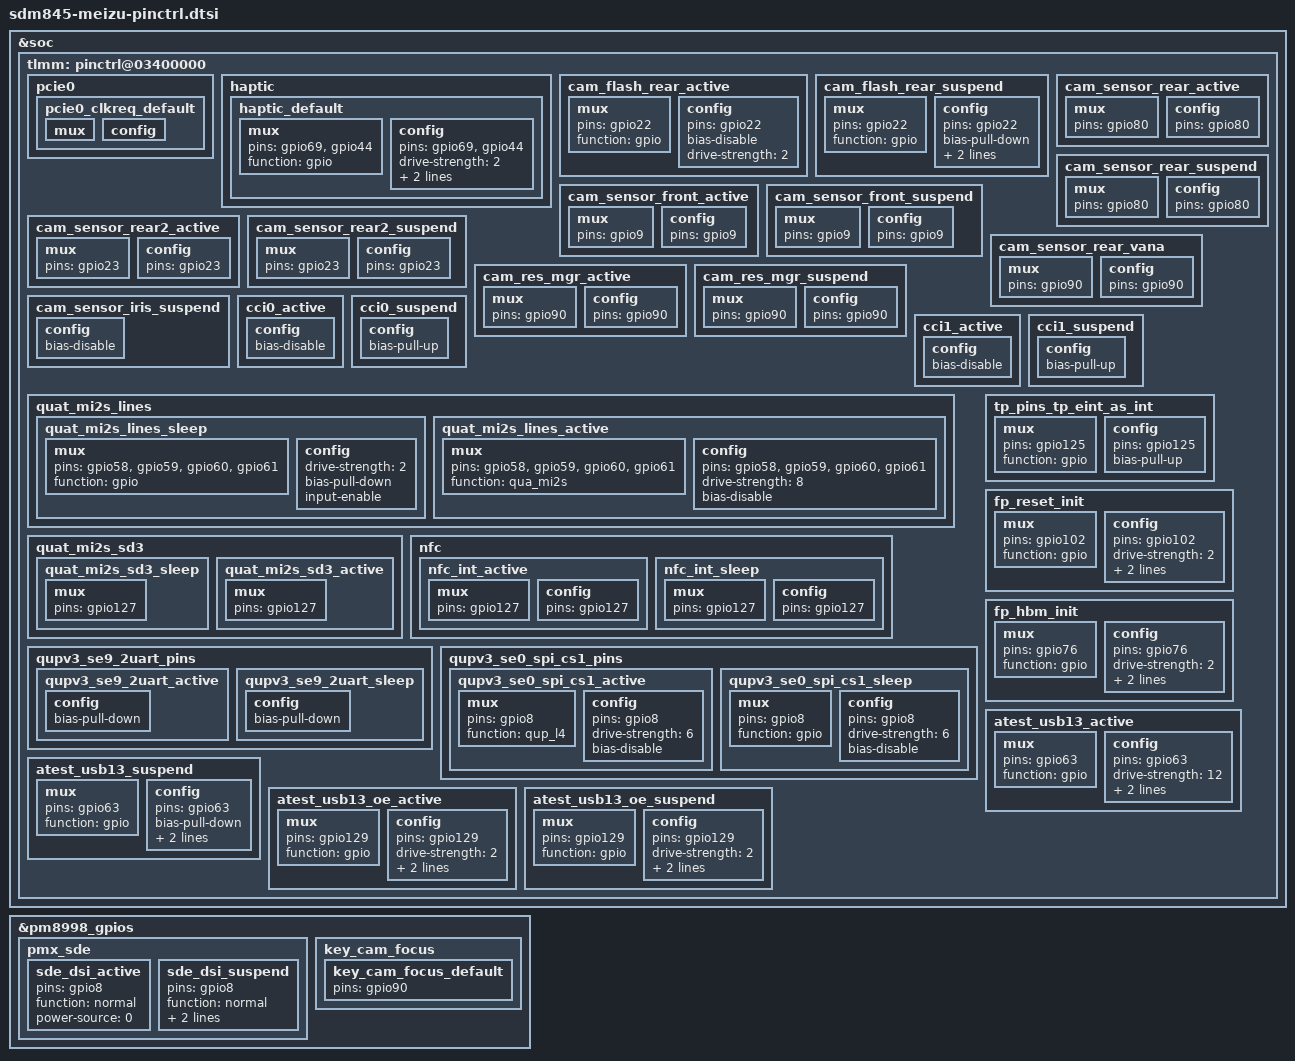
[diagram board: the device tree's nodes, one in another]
/* Copyright (c) 2022, MeizuCustoms enthusiasts
 *
 * This program is free software; you can redistribute it and/or modify
 * it under the terms of the GNU General Public License version 2 and
 * only version 2 as published by the Free Software Foundation.
 *
 * This program is distributed in the hope that it will be useful,
 * but WITHOUT ANY WARRANTY; without even the implied warranty of
 * MERCHANTABILITY or FITNESS FOR A PARTICULAR PURPOSE.  See the
 * GNU General Public License for more details.
 */

/* TLMM */
&soc {
	tlmm: pinctrl@03400000 {
        /delete-node/ storage_cd;
        /delete-node/ spkr_i2s_clk_pin;
        /delete-node/ ext_bridge_mux;
        /delete-node/ pmx_ts_int_active;
        /delete-node/ pmx_ts_int_suspend;
        /delete-node/ pmx_ts_reset_active;
        /delete-node/ pmx_ts_reset_suspend;
        /delete-node/ pmx_ts_release;
        /delete-node/ pmx_sde;
        /delete-node/ ts_mux;
        /delete-node/ cam_sensor_fisheye_active;
        /delete-node/ cam_sensor_fisheye_suspend;
        /delete-node/ cam_sensor_depth_active;
        /delete-node/ cam_sensor_depth_suspend;
        /delete-node/ max_rst_active;
        /delete-node/ max_rst_suspend;
        /delete-node/ max_6dof_active;
        /delete-node/ max_6dof_suspend;
        /delete-node/ ap2mdm;
        /delete-node/ mdm2ap;

        pcie0 {
            /delete-node/ pcie0_3v3_on;
            /delete-node/ pcie0_1v5_on;

            /* empty nodes (c) meizu inc */
            pcie0_clkreq_default: pcie0_clkreq_default {
                mux {
                    /delete-property/ pins;
                    /delete-property/ function;
                };

                config {
                    /delete-property/ pins;
                    /delete-property/ drive-strength;
                    /delete-property/ bias-pull-up;
                };
            };
        };

        haptic {
            haptic_default: haptic_default {
                mux {
                    pins = "gpio69", "gpio44";
                    function = "gpio";
                };

                config {
                    pins = "gpio69", "gpio44";
                    drive-strength = <2>;
                    bias-pull-up;
                    input-enable;
                };
            };
        };

        cam_flash_rear_active: cam_flash_rear_active {
            mux {
                pins = "gpio22";
                function = "gpio";
            };

            config {
                pins = "gpio22";
                bias-disable;
                drive-strength = <2>;
            };
        };

        cam_flash_rear_suspend: cam_flash_rear_suspend {
            mux {
                pins = "gpio22";
                function = "gpio";
            };

            config {
                pins = "gpio22";
                bias-pull-down;
                drive-strength = <2>;
                output-low;
            };
        };

        cam_sensor_rear_active: cam_sensor_rear_active {
            mux {
                pins = "gpio80";
            };
            config {
                pins = "gpio80";
            };
        };

        cam_sensor_rear_suspend: cam_sensor_rear_suspend {
            mux {
                pins = "gpio80";
            };
            config {
                pins = "gpio80";
            };
        };

        cam_sensor_front_active: cam_sensor_front_active {
            mux {
                pins = "gpio9";
            };
            config {
                pins = "gpio9";
            };
        };

        cam_sensor_front_suspend: cam_sensor_front_suspend {
            mux {
                pins = "gpio9";
            };
            config {
                pins = "gpio9";
            };
        };

        cam_sensor_rear2_active: cam_sensor_rear2_active {
            mux {
                pins = "gpio23";
            };
            config {
                pins = "gpio23";
            };
        };

        cam_sensor_rear2_suspend: cam_sensor_rear2_suspend {
            mux {
                pins = "gpio23";
            };
            config {
                pins = "gpio23";
            };
        };

        cam_sensor_rear_vana: cam_sensor_rear_vana {
            mux {
                pins = "gpio90";
            };
            config {
                pins = "gpio90";
            };
        };

        cam_res_mgr_active: cam_res_mgr_active {
            mux {
                pins = "gpio90";
            };
            config {
                pins = "gpio90";
            };
        };

        cam_res_mgr_suspend: cam_res_mgr_suspend {
            mux {
                pins = "gpio90";
            };
            config {
                pins = "gpio90";
            };
        };

        cam_sensor_iris_suspend: cam_sensor_iris_suspend {
            config {
                bias-disable;
                /delete-property/ bias-pull-down;
            };
        };

        cci0_active: cci0_active {
            config {
                bias-disable;
                /delete-property/ bias-pull-up;
            };
        };

        cci0_suspend: cci0_suspend {
            config {
                bias-pull-up;
                /delete-property/ bias-pull-down;
            };
        };
        
        cci1_active: cci1_active {
            config {
                bias-disable;
                /delete-property/ bias-pull-up;
            };
        };

        cci1_suspend: cci1_suspend {
            config {
                bias-pull-up;
                /delete-property/ bias-pull-down;
            };
        };

        quat_mi2s_lines {
            quat_mi2s_lines_sleep: quat_mi2s_lines_sleep {
                mux {
                    pins = "gpio58", "gpio59", "gpio60", "gpio61";
                    function = "gpio";
                };

                config {
                    drive-strength = <2>;
                    bias-pull-down;
                    input-enable;
                };
            };

            quat_mi2s_lines_active: quat_mi2s_lines_active {
                mux {
                    pins = "gpio58", "gpio59", "gpio60", "gpio61";
                    function = "qua_mi2s";
                };

                config {
                    pins = "gpio58", "gpio59", "gpio60", "gpio61";
                    drive-strength = <8>;
                    bias-disable;
                };
            };
        };

        quat_mi2s_sd3 {
            quat_mi2s_sd3_sleep: quat_mi2s_sd3_sleep {
                mux {
                    pins = "gpio127";
                };
            };

            quat_mi2s_sd3_active: quat_mi2s_sd3_active {
                mux {
                    pins = "gpio127";
                };
            };
        };

        nfc {
            nfc_int_active: nfc_int_active {
                mux {
                    pins = "gpio127";
                };
                config {
                    pins = "gpio127";
                };
            };

            nfc_int_sleep: nfc_int_sleep {
                mux {
                    pins = "gpio127";
                };
                config {
                    pins = "gpio127";
                };
            };
        };

        qupv3_se9_2uart_pins: qupv3_se9_2uart_pins {
            qupv3_se9_2uart_active: qupv3_se9_2uart_active {
                config {
                    bias-pull-down;
                    /delete-property/ bias-disable;
                };
            };
            qupv3_se9_2uart_sleep: qupv3_se9_2uart_sleep {
                config {
                    bias-pull-down;
                    /delete-property/ bias-disable;
                };
            };
        };

        qupv3_se0_spi_cs1_pins {
            qupv3_se0_spi_cs1_active: qupv3_se0_spi_cs1_active {
                mux {
                    pins = "gpio8";
                    function = "qup_l4";
                };

                config {
                    pins = "gpio8";
                    drive-strength = <6>;
                    bias-disable;
                };
            };

            qupv3_se0_spi_cs1_sleep: qupv3_se0_spi_cs1_sleep {
                mux {
                    pins = "gpio8";
                    function = "gpio";
                };

                config {
                    pins = "gpio8";
                    drive-strength = <6>;
                    bias-disable;
                };
            };
        };

        tp_pins_tp_eint_as_int: tp_pins_tp_eint_as_int {
            mux {
                pins = "gpio125";
                function = "gpio";
            };

            config {
                pins = "gpio125";
                bias-pull-up;
            };
        };

        fp_reset_init: fp_reset_init {
            mux {
                pins = "gpio102";
                function = "gpio";
            };

            config {
                pins = "gpio102";
                drive-strength = <2>;
                bias-disable;
                output-low;
            };
        };

        fp_hbm_init: fp_hbm_init {
            mux {
                pins = "gpio76";
                function = "gpio";
            };

            config {
                pins = "gpio76";
                drive-strength = <2>;
                bias-disable;
                output-low;
            };
        };

        atest_usb13_active: atest_usb13_active {
            mux {
                pins = "gpio63";
                function = "gpio";
            };

            config {
                pins = "gpio63";
                drive-strength = <12>;
                bias-pull-up;
                output-high;
            };
        };

        atest_usb13_suspend: atest_usb13_suspend {
            mux {
                pins = "gpio63";
                function = "gpio";
            };

            config {
                pins = "gpio63";
                bias-pull-down;
                drive-strength = <2>;
                output-low;
            };
        };

        atest_usb13_oe_active: atest_usb13_oe_active {
            mux {
                pins = "gpio129";
                function = "gpio";
            };

            config {
                pins = "gpio129";
                drive-strength = <2>;
                bias-pull-down;
                output-low;
            };
        };

        atest_usb13_oe_suspend: atest_usb13_oe_suspend {
            mux {
                pins = "gpio129";
                function = "gpio";
            };

            config {
                pins = "gpio129";
                drive-strength = <2>;
                bias-pull-up;
                output-high;
            };
        };
    };
};

/* PM8998 */
&pm8998_gpios {
    /delete-node/ led_bt;
    /delete-node/ led_wifi;
    /delete-node/ camera_rear_avdd_en;

    pmx_sde: pmx_sde {
        sde_dsi_active: sde_dsi_active {
            pins = "gpio8";
            function = "normal";
            power-source = <0>;
        };

        sde_dsi_suspend: sde_dsi_suspend {
            pins = "gpio8";
            function = "normal";
            power-source = <0>;
            bias-pull-down;
        };
    };

    key_cam_focus {
        key_cam_focus_default: key_cam_focus_default {
            pins = "gpio90";
        };
    };
};
